# STM32H757xx_CM4 register map
File version: 1.0
Registers are 32-bit, read-write, reset 0x0 unless marked. A register's access mark holds for its fields unless they carry their own. Offsets are from the block's base; [hi:lo] are bit positions; {n}, {i} and the like mark numbered series.

## SYSCFG — System configuration controller
Base 0x58000400
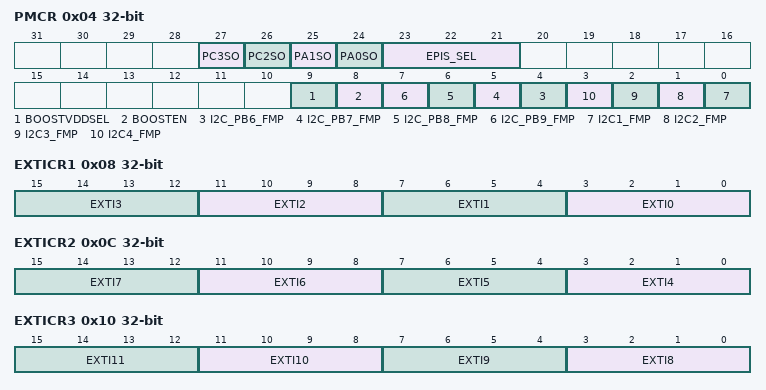
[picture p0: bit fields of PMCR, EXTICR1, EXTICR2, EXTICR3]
0x04 PMCR — SYSCFG peripheral mode configuration register
  [27] PC3SO — PC3 Switch Open
  [26] PC2SO — PC2 Switch Open
  [25] PA1SO — PA1 Switch Open
  [24] PA0SO — PA0 Switch Open
  [23:21] EPIS_SEL — Ethernet PHY Interface Selection
    0=MII (ETH Media MII interface); 4=RMII (ETH Media RMII interface)
  [9] BOOSTVDDSEL — Analog switch supply source selection : VDD/VDDA
  [8] BOOSTEN — I/O analog switch voltage booster enable
  [n-2] I2C_PB{n}_FMP (n=6..9) — I2C PB{n} Fast mode plus
  [n-1] I2C{n}_FMP (n=1..4) — I2C{n} Fast mode plus
0x08 EXTICR1 — SYSCFG external interrupt configuration registers
  [4n+3:4n] EXTI{n} (n=0..3) — EXTI {n} configuration
0x0C EXTICR2 — SYSCFG external interrupt configuration registers
  [4n-13:4n-16] EXTI{n} (n=4..7) — EXTI {n} configuration
0x10 EXTICR3 — SYSCFG external interrupt configuration registers
  [4n-29:4n-32] EXTI{n} (n=8..11) — EXTI {n} configuration
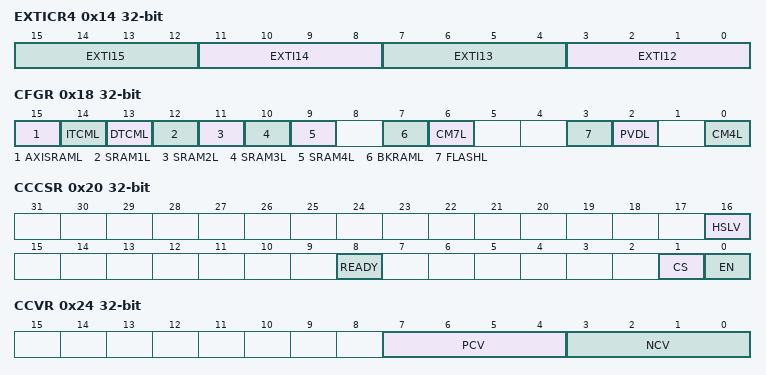
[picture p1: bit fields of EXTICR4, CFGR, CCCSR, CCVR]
0x14 EXTICR4 — SYSCFG external interrupt configuration registers
  [4n-45:4n-48] EXTI{n} (n=12..15) — EXTI {n} configuration
0x18 CFGR — SYSCFG configuration registers
  [15] AXISRAML — AXISRAM double ECC error lock bit
  [14] ITCML — ITCM double ECC error lock bit
  [13] DTCML — DTCM double ECC error lock bit
  [13-n] SRAM{n}L (n=1..4) — SRAM{n} double ECC error lock bit
  [7] BKRAML — Backup SRAM double ECC error lock bit
  [6] CM7L — Cortex-M7 LOCKUP (Hardfault) output enable bit
  [3] FLASHL — FLASH double ECC error lock bit
  [2] PVDL — PVD lock enable bit
  [0] CM4L — Cortex-M4 LOCKUP (Hardfault) output enable bit
0x20 CCCSR — SYSCFG compensation cell control/status register
  [16] HSLV — High-speed at low-voltage
  [8] READY — I/O compensation cell ready flag
  [1] CS — I/O compensation cell code selection
  [0] EN — I/O compensation cell enable
0x24 CCVR — SYSCFG compensation cell value register
  [7:4] PCV — PMOS compensation value
  [3:0] NCV — NMOS compensation value
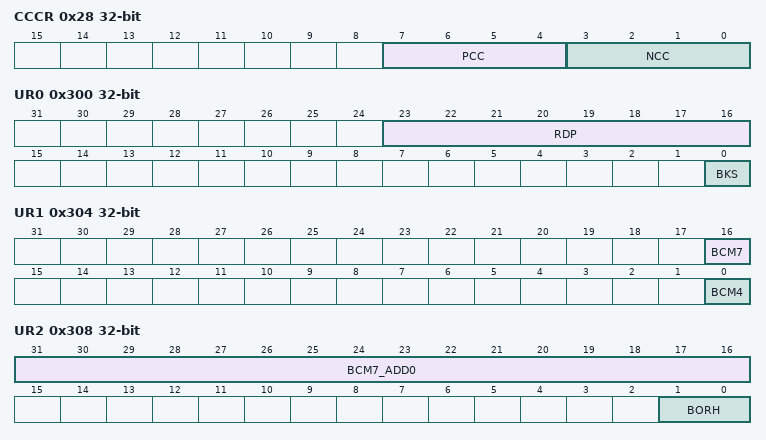
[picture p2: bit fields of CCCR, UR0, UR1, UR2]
0x28 CCCR — SYSCFG compensation cell code register
  [7:4] PCC — PMOS compensation code
  [3:0] NCC — NMOS compensation code
0x2C PWRCR — PWR control register
  [0] ODEN — PWR overdrive enable
0x124 PKGR — SYSCFG package register
  [3:0] PKG — Package type
0x300 UR0 — SYSCFG user register 0
  [23:16] RDP — Readout protection
  [0] BKS — Bank Swap
0x304 UR1 — SYSCFG user register 1
  [16] BCM7 — Boot Cortex-M7
  [0] BCM4 — Boot Cortex-M4
0x308 UR2 — SYSCFG user register 2
  [31:16] BCM7_ADD0 — Boot Cortex-M7 Address 0
  [1:0] BORH — Brown Out Reset High level
    3=HIGH_RESET_LEVEL; 2=MEDIUM_RESET_LEVEL; 1=LOW_RESET_LEVEL; 0=OFF_RESET_LEVEL
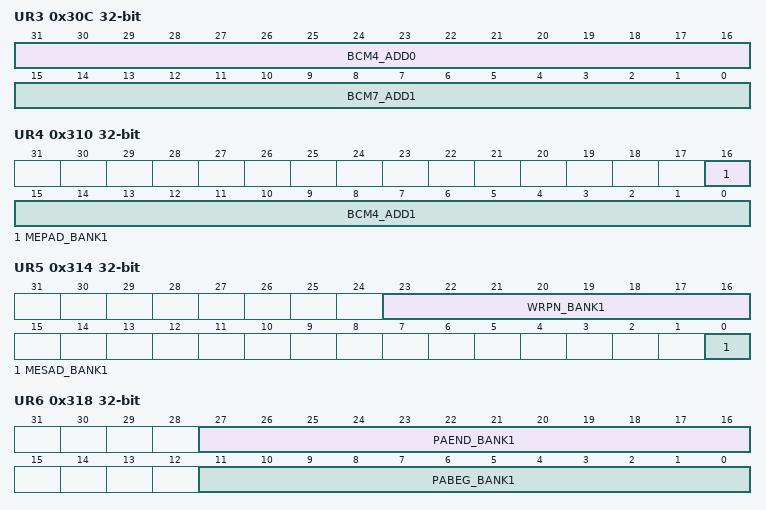
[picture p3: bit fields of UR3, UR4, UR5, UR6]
0x30C UR3 — SYSCFG user register 3
  [31:16] BCM4_ADD0 — Boot Cortex-M4 Address 0
  [15:0] BCM7_ADD1 — Boot Cortex-M7 Address 1
0x310 UR4 — SYSCFG user register 4
  [16] MEPAD_BANK1 — Mass Erase Protected Area Disabled for bank 1
  [15:0] BCM4_ADD1 — Boot Cortex-M4 Address 1
0x314 UR5 — SYSCFG user register 5
  [23:16] WRPN_BANK1 — Write protection for flash bank 1
  [0] MESAD_BANK1 — Mass erase secured area disabled for bank 1
0x318 UR6 — SYSCFG user register 6
  [27:16] PAEND_BANK1 — Protected area end address for bank 1
  [11:0] PABEG_BANK1 — Protected area start address for bank 1
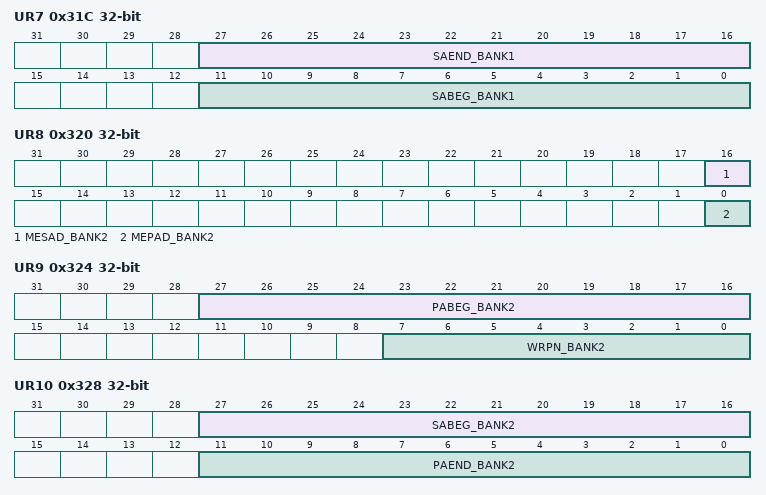
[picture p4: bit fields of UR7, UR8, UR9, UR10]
0x31C UR7 — SYSCFG user register 7
  [27:16] SAEND_BANK1 — Secured area end address for bank 1
  [11:0] SABEG_BANK1 — Secured area start address for bank 1
0x320 UR8 — SYSCFG user register 8
  [16] MESAD_BANK2 — Mass Erase Secured Area Disabled for bank 2
  [0] MEPAD_BANK2 — Mass erase Protected area disabled for bank 2
0x324 UR9 — SYSCFG user register 9
  [27:16] PABEG_BANK2 — Protected area start address for bank 2
  [7:0] WRPN_BANK2 — Write protection for flash bank 2
0x328 UR10 — SYSCFG user register 10
  [27:16] SABEG_BANK2 — Secured area start address for bank 2
  [11:0] PAEND_BANK2 — Protected area end address for bank 2
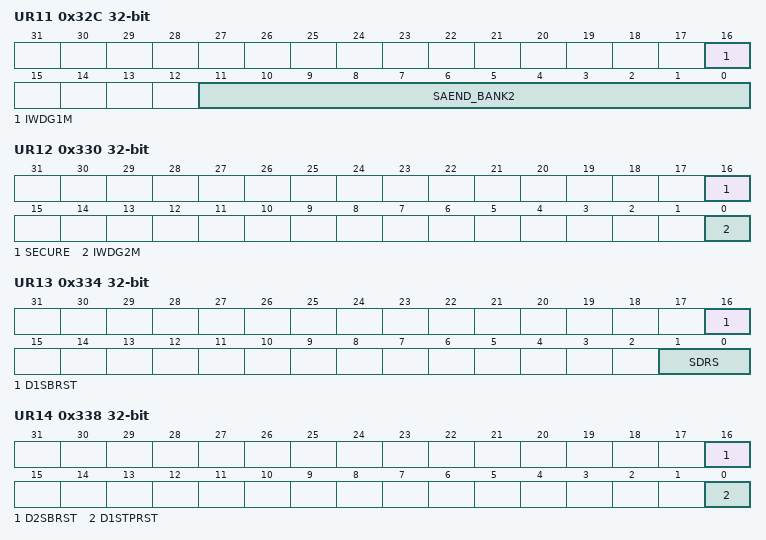
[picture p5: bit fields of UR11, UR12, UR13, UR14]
0x32C UR11 — SYSCFG user register 11
  [16] IWDG1M — Independent Watchdog 1 mode (SW or HW)
    0=SW_CONTROL_MODE; 1=HW_CONTROL_MODE
  [11:0] SAEND_BANK2 — Secured area end address for bank 2
0x330 UR12 — SYSCFG user register 12
  [16] SECURE — Secure mode status
  [0] IWDG2M — Independent Watchdog 2 mode (SW or HW)
    0=SW_CONTROL_MODE; 1=HW_CONTROL_MODE
0x334 UR13 — SYSCFG user register 13
  [16] D1SBRST — D1 Standby reset
  [1:0] SDRS — Secured DTCM RAM Size
    0=SIZE_2KB; 1=SIZE_4KB; 2=SIZE_8KB; 3=SIZE_16KB
0x338 UR14 — SYSCFG user register 14
  [16] D2SBRST — D2 Standby Reset
  [0] D1STPRST — D1 Stop Reset
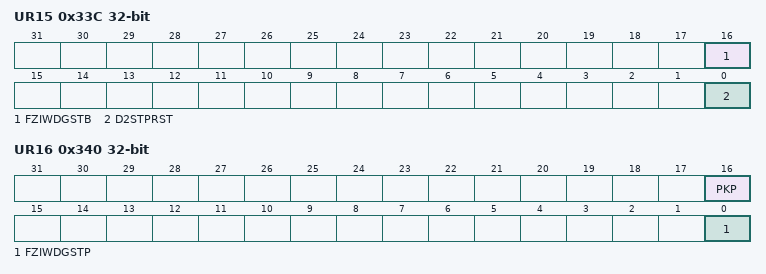
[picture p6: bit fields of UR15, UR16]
0x33C UR15 — SYSCFG user register 15
  [16] FZIWDGSTB — Freeze independent watchdogs in Standby mode
  [0] D2STPRST — D2 Stop Reset
0x340 UR16 — SYSCFG user register 16
  [16] PKP — Private key programmed
  [0] FZIWDGSTP — Freeze independent watchdogs in Stop mode
0x344 UR17 — SYSCFG user register 17
  [0] IOHSLV — I/O high speed / low voltage
